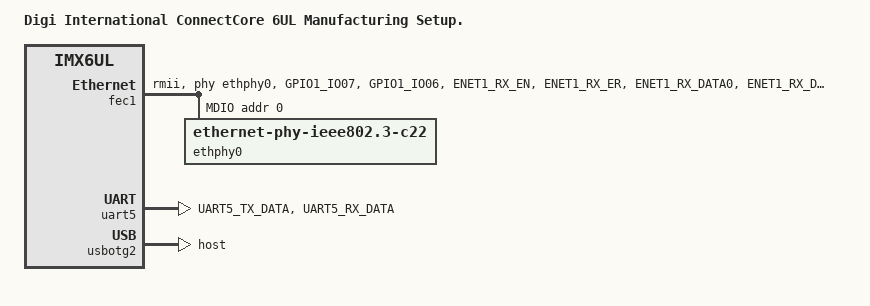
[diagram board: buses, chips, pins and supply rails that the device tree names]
/*
 * Copyright (C) 2017-2024, Digi International Inc.
 *
 * The code contained herein is licensed under the GNU General Public
 * License. You may obtain a copy of the GNU General Public License
 * Version 2 or later at the following locations:
 *
 * http://www.opensource.org/licenses/gpl-license.html
 * http://www.gnu.org/copyleft/gpl.html
 */
/dts-v1/;
#include <dt-bindings/input/input.h>
/* i.MX6 UltraLite CPU */
#include "imx6ul.dtsi"
/* ConnectCore 6UL (wireless/bluetooth variant) */
#include "imx6ul-ccimx6ul-wb.dtsi"

/ {
	model = "Digi International ConnectCore 6UL Manufacturing Setup.";
	compatible = "digi,ccimx6ulstarter", "digi,ccimx6ul", "fsl,imx6ul";
	digi,machine,name = "ccimx6ul_mfg_rf";
};

&fec1 {
	pinctrl-names = "default";
	pinctrl-0 = <&pinctrl_enet1>, <&pinctrl_enet1_gpio>;
	phy-mode = "rmii";
	phy-handle = <&ethphy0>;
	phy-reset-gpios = <&mca_gpio 7 GPIO_ACTIVE_LOW>;
	phy-reset-duration = <26>;
	digi,phy-reset-in-suspend;
	status = "okay";

	mdio {
		#address-cells = <1>;
		#size-cells = <0>;

		ethphy0: ethernet-phy@0 {
			compatible = "ethernet-phy-ieee802.3-c22";
			clocks = <&clks IMX6UL_CLK_ENET_REF>;
			clock-names = "refclk";
			smsc,disable-energy-detect;
			reg = <0>;
		};
	};
};

/* UART5 (Console) */
&uart5 {
	pinctrl-names = "default";
	pinctrl-0 = <&pinctrl_uart5>;
	status = "okay";
};

&usbotg2 {
	dr_mode = "host";
	power-active-high;
	disable-over-current;
	status = "okay";
};

&iomuxc {
	pinctrl-names = "default";
	
	imx6ul-ccimx6ul {
		pinctrl_uart5: uart5grp {
			fsl,pins = <
				MX6UL_PAD_UART5_TX_DATA__UART5_DCE_TX	0x1b0b1
				MX6UL_PAD_UART5_RX_DATA__UART5_DCE_RX	0x1b0b1
			>;
		};

		pinctrl_enet1: enet1grp {
			fsl,pins = <
				MX6UL_PAD_GPIO1_IO07__ENET1_MDC		0x1b0b0
				MX6UL_PAD_GPIO1_IO06__ENET1_MDIO	0x1b0b0
				MX6UL_PAD_ENET1_RX_EN__ENET1_RX_EN	0x1b0b0
				MX6UL_PAD_ENET1_RX_ER__ENET1_RX_ER	0x1b0b0
				MX6UL_PAD_ENET1_RX_DATA0__ENET1_RDATA00	0x1b0b0
				MX6UL_PAD_ENET1_RX_DATA1__ENET1_RDATA01	0x1b0b0
				MX6UL_PAD_ENET1_TX_EN__ENET1_TX_EN	0x1b0b0
				MX6UL_PAD_ENET1_TX_DATA0__ENET1_TDATA00	0x1b0b0
				MX6UL_PAD_ENET1_TX_DATA1__ENET1_TDATA01	0x1b0b0
				MX6UL_PAD_ENET1_TX_CLK__ENET1_REF_CLK1	0x40017051
			>;
		};

		pinctrl_enet1_gpio: enet1gpiogrp {
			fsl,pins = <
				/* ENET1_PWR */
				MX6UL_PAD_LCD_HSYNC__GPIO3_IO02		0x1b0b0
				/* ENET1_INT */
				MX6UL_PAD_LCD_DATA04__GPIO3_IO09	0x1b0b0
			>;
		};
	};
};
